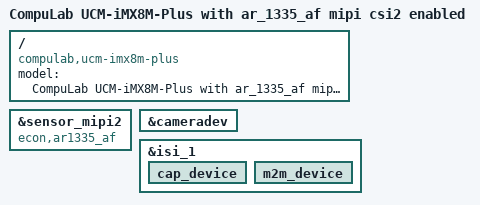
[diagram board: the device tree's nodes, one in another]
// SPDX-License-Identifier: (GPL-2.0+ OR MIT)
/*
 * Copyright 2021 CompuLab
 */

/dts-v1/;

#include "ucm-imx8m-plus.dts"
#include "ucm-imx8m-plus_mipi-csi2.dtsi"

/ {
	model = "CompuLab UCM-iMX8M-Plus with ar_1335_af mipi csi2 enabled";
	compatible = "compulab,ucm-imx8m-plus", "fsl,imx8mp";
};

&sensor_mipi2 {
	compatible = "econ,ar1335_af", "ar1335_af";
};

&cameradev {
	status = "okay";
};

&isi_1 {
	status = "okay";

	cap_device {
		status = "okay";
	};

	m2m_device {
		status = "okay";
	};
};
